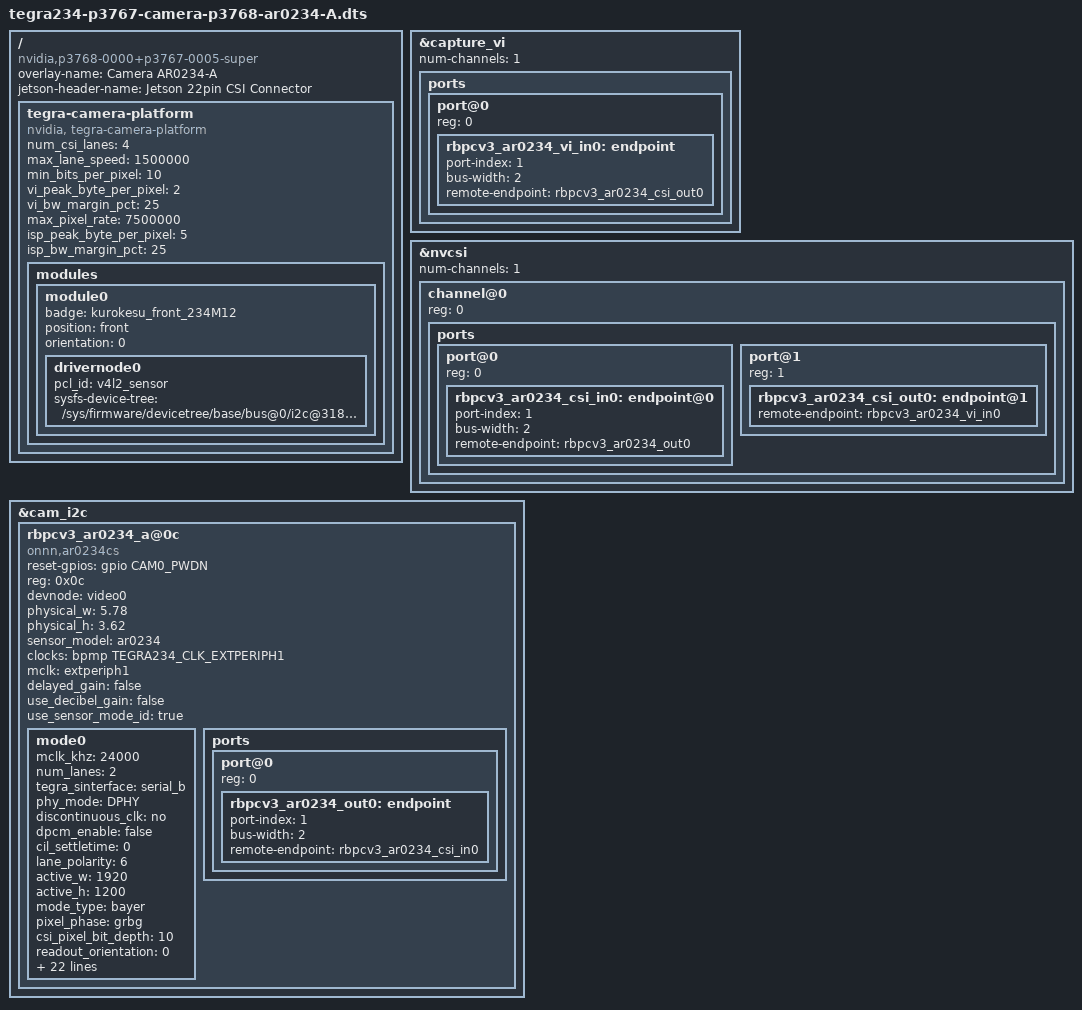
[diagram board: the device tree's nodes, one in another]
// SPDX-License-Identifier: GPL-2.0-only
// SPDX-FileCopyrightText: Copyright (c) 2025, NVIDIA CORPORATION & AFFILIATES. All rights reserved.
// SPDX-FileCopyrightText: Copyright (c) 2026, UAB Kurokesu. All rights reserved.

/dts-v1/;
/plugin/;

#define CAM0_PWDN	TEGRA234_MAIN_GPIO(H, 6)
#define CAM1_PWDN	TEGRA234_MAIN_GPIO(AC, 0)
#define CAM_I2C_MUX 	TEGRA234_AON_GPIO(CC, 3)

#include <dt-bindings/tegra234-p3767-0000-common.h>
#include <dt-bindings/clock/tegra234-clock.h>

/ {
	overlay-name = "Camera AR0234-A";
	jetson-header-name = "Jetson 22pin CSI Connector";
	compatible = "nvidia,p3768-0000+p3767-0005-super", JETSON_COMPATIBLE_P3768;
	/* AR0234 connected to cam0 port */

	/* fragment@0: VI (Video Input) — захват кадров */
	fragment@0 {
		target = <&capture_vi>;
		__overlay__ {
			num-channels = <1>;
			ports {
				#address-cells = <1>;
				#size-cells = <0>;
				port@0 {
					reg = <0>;
					rbpcv3_ar0234_vi_in0: endpoint {
						port-index = <1>;
						bus-width = <2>;
						remote-endpoint = <&rbpcv3_ar0234_csi_out0>;
					};
				};
			};
		};
	};

	/* fragment@1: Camera Platform (создается оверлеем, в базе нет) */
	fragment@1 {
		target-path = "/";
		__overlay__ {
			tegra-camera-platform {
				compatible = "nvidia, tegra-camera-platform";
				num_csi_lanes = <4>;
				max_lane_speed = <1500000>;
				min_bits_per_pixel = <10>;
				vi_peak_byte_per_pixel = <2>;
				vi_bw_margin_pct = <25>;
				max_pixel_rate = <7500000>;
				isp_peak_byte_per_pixel = <5>;
				isp_bw_margin_pct = <25>;
				modules {
					module0 {
						badge = "kurokesu_front_234M12";
						position = "front";
						orientation = "0";
						drivernode0 {
							pcl_id = "v4l2_sensor";
							sysfs-device-tree = "/sys/firmware/devicetree/base/bus@0/i2c@3180000/rbpcv3_ar0234_a@0c";
						};
					};
				};
			};
		};
	};

	/* fragment@2: NVCSI — приём MIPI-потока */
	fragment@2 {
		target = <&nvcsi>;
		__overlay__ {
			num-channels = <1>;
			#address-cells = <1>;
			#size-cells = <0>;
			channel@0 {
				reg = <0>;
				ports {
					#address-cells = <1>;
					#size-cells = <0>;
					port@0 {
						reg = <0>;
						rbpcv3_ar0234_csi_in0: endpoint@0 {
							port-index = <1>;
							bus-width = <2>;
							remote-endpoint = <&rbpcv3_ar0234_out0>;
						};
					};
					port@1 {
						reg = <1>;
						rbpcv3_ar0234_csi_out0: endpoint@1 {
							remote-endpoint = <&rbpcv3_ar0234_vi_in0>;
						};
					};
				};
			};
		};
	};

	/* fragment@3: I2C-шина камеры + узел сенсора AR0234 */
	fragment@3 {
		target = <&cam_i2c>;
		__overlay__ {
			status = "okay";
			#address-cells = <1>;
			#size-cells = <0>;
			rbpcv3_ar0234_a@0c {
				reset-gpios = <&gpio CAM0_PWDN GPIO_ACTIVE_HIGH>;
				compatible = "onnn,ar0234cs";
				/* I2C device address */
				reg = <0x0c>;
				/* V4L2 device node location */
				devnode = "video0";
				/* Physical dimensions of sensor */
				physical_w = "5.78";
				physical_h = "3.62";
				sensor_model = "ar0234";

				clocks = <&bpmp TEGRA234_CLK_EXTPERIPH1>;
				clock-names = "extperiph1";
				mclk = "extperiph1";

				/* if true, delay gain setting by one frame to be in sync with exposure */
				delayed_gain = "false";

				/* Convert Gain to unit of dB (decibel) before passing to kernel driver */
				use_decibel_gain = "false";

				/* enable CID_SENSOR_MODE_ID for sensor modes selection */
				use_sensor_mode_id = "true";

				mode0 { /* AR0234_MODE_1920X1200_2LANE */
					mclk_khz = "24000";
					num_lanes = "2";
					tegra_sinterface = "serial_b";
					phy_mode = "DPHY";
					discontinuous_clk = "no";
					dpcm_enable = "false";
					cil_settletime = "0";
					lane_polarity = "6";
					active_w = "1920";
					active_h = "1200";
					mode_type = "bayer";
					pixel_phase = "grbg";
					csi_pixel_bit_depth = "10";
					readout_orientation = "0";
					line_length = "2448";
					inherent_gain = "1";
					mclk_multiplier = "4";
					pix_clk_hz = "180000000";
					gain_factor = "100";
					framerate_factor = "1000000";
					exposure_factor = "1000000";
					min_gain_val = "169"; /* 1.68421 */
					max_gain_val = "1600"; /* 16.0 */
					step_gain_val = "1"; /* 0.01 */
					default_gain = "169";
					min_hdr_ratio = "1";
					max_hdr_ratio = "1";
					min_framerate = "2000000"; /* 2.0 fps */
					max_framerate = "30000000"; /* 30.0 fps */
					step_framerate = "1";
					default_framerate = "30000000"; /* 30.0 fps */
					min_exp_time = "28"; /* us */
					max_exp_time = "499909"; /* us */
					step_exp_time = "1";
					default_exp_time = "217"; /* us */
					embedded_metadata_height = "0";
				};
				ports {
					#address-cells = <1>;
					#size-cells = <0>;
					port@0 {
						reg = <0>;
						rbpcv3_ar0234_out0: endpoint {
							port-index = <1>;
							bus-width = <2>;
							remote-endpoint = <&rbpcv3_ar0234_csi_in0>;
						};
					};
				};
			};
		};
	};
};
